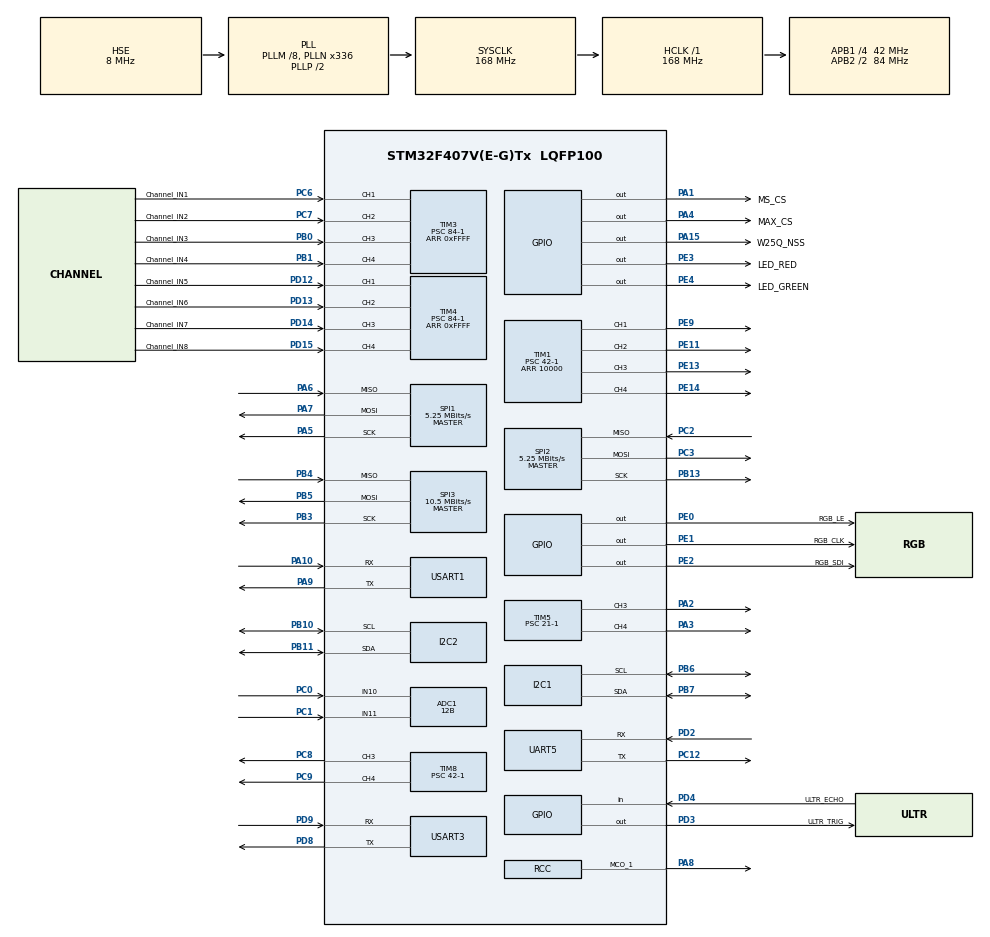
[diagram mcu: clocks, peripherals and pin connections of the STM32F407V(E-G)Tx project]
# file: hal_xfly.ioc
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ADC1.Channel-0\#ChannelRegularConversion=ADC_CHANNEL_10
ADC1.Channel-1\#ChannelRegularConversion=ADC_CHANNEL_11
ADC1.ClockPrescaler=ADC_CLOCK_SYNC_PCLK_DIV6
ADC1.ContinuousConvMode=ENABLE
ADC1.DMAContinuousRequests=DISABLE
ADC1.DataAlign=ADC_DATAALIGN_RIGHT
ADC1.DiscontinuousConvMode=DISABLE
ADC1.EOCSelection=ADC_EOC_SINGLE_CONV
ADC1.EnableAnalogWatchDog=false
ADC1.ExternalTrigConv=ADC_SOFTWARE_START
ADC1.ExternalTrigConvEdge=ADC_EXTERNALTRIGCONVEDGE_NONE
ADC1.InjNumberOfConversion=0
ADC1.NbrOfConversion=2
ADC1.NbrOfConversionFlag=1
ADC1.Rank-0\#ChannelRegularConversion=1
ADC1.Rank-1\#ChannelRegularConversion=2
ADC1.Resolution=ADC_RESOLUTION_12B
ADC1.SamplingTime-0\#ChannelRegularConversion=ADC_SAMPLETIME_56CYCLES
ADC1.SamplingTime-1\#ChannelRegularConversion=ADC_SAMPLETIME_56CYCLES
ADC1.ScanConvMode=ENABLE
ADC1.master=1
Dma.ADC1.4.Direction=DMA_PERIPH_TO_MEMORY
Dma.ADC1.4.FIFOMode=DMA_FIFOMODE_DISABLE
Dma.ADC1.4.Instance=DMA2_Stream0
Dma.ADC1.4.MemDataAlignment=DMA_MDATAALIGN_HALFWORD
Dma.ADC1.4.MemInc=DMA_MINC_ENABLE
Dma.ADC1.4.Mode=DMA_NORMAL
Dma.ADC1.4.PeriphDataAlignment=DMA_PDATAALIGN_HALFWORD
Dma.ADC1.4.PeriphInc=DMA_PINC_DISABLE
Dma.ADC1.4.Priority=DMA_PRIORITY_LOW
Dma.Request0=USART3_RX
Dma.Request1=USART3_TX
Dma.Request2=USART1_RX
Dma.Request3=USART1_TX
Dma.Request4=ADC1
Dma.USART1_RX.2.Direction=DMA_PERIPH_TO_MEMORY
Dma.USART1_RX.2.FIFOMode=DMA_FIFOMODE_DISABLE
Dma.USART1_RX.2.Instance=DMA2_Stream2
Dma.USART1_RX.2.MemDataAlignment=DMA_MDATAALIGN_BYTE
Dma.USART1_RX.2.MemInc=DMA_MINC_ENABLE
Dma.USART1_RX.2.Mode=DMA_NORMAL
Dma.USART1_RX.2.PeriphDataAlignment=DMA_PDATAALIGN_BYTE
Dma.USART1_RX.2.PeriphInc=DMA_PINC_DISABLE
Dma.USART1_RX.2.Priority=DMA_PRIORITY_HIGH
Dma.USART1_TX.3.Direction=DMA_MEMORY_TO_PERIPH
Dma.USART1_TX.3.FIFOMode=DMA_FIFOMODE_DISABLE
Dma.USART1_TX.3.Instance=DMA2_Stream7
Dma.USART1_TX.3.MemDataAlignment=DMA_MDATAALIGN_BYTE
Dma.USART1_TX.3.MemInc=DMA_MINC_ENABLE
Dma.USART1_TX.3.Mode=DMA_NORMAL
Dma.USART1_TX.3.PeriphDataAlignment=DMA_PDATAALIGN_BYTE
Dma.USART1_TX.3.PeriphInc=DMA_PINC_DISABLE
Dma.USART1_TX.3.Priority=DMA_PRIORITY_HIGH
Dma.USART3_RX.0.Direction=DMA_PERIPH_TO_MEMORY
Dma.USART3_RX.0.FIFOMode=DMA_FIFOMODE_DISABLE
Dma.USART3_RX.0.Instance=DMA1_Stream1
Dma.USART3_RX.0.MemDataAlignment=DMA_MDATAALIGN_BYTE
Dma.USART3_RX.0.MemInc=DMA_MINC_ENABLE
Dma.USART3_RX.0.Mode=DMA_NORMAL
Dma.USART3_RX.0.PeriphDataAlignment=DMA_PDATAALIGN_BYTE
Dma.USART3_RX.0.PeriphInc=DMA_PINC_DISABLE
Dma.USART3_RX.0.Priority=DMA_PRIORITY_HIGH
Dma.USART3_TX.1.Direction=DMA_MEMORY_TO_PERIPH
Dma.USART3_TX.1.FIFOMode=DMA_FIFOMODE_DISABLE
Dma.USART3_TX.1.Instance=DMA1_Stream3
Dma.USART3_TX.1.MemDataAlignment=DMA_MDATAALIGN_BYTE
Dma.USART3_TX.1.MemInc=DMA_MINC_ENABLE
Dma.USART3_TX.1.Mode=DMA_NORMAL
Dma.USART3_TX.1.PeriphDataAlignment=DMA_PDATAALIGN_BYTE
Dma.USART3_TX.1.PeriphInc=DMA_PINC_DISABLE
Dma.USART3_TX.1.Priority=DMA_PRIORITY_HIGH
Mcu.Family=STM32F4
Mcu.Name=STM32F407V(E-G)Tx
Mcu.Package=LQFP100
NVIC.DMA1_Stream1_IRQn=true\:0\:0\:false\:false\:true\:false
NVIC.DMA1_Stream3_IRQn=true\:0\:0\:false\:false\:true\:false
NVIC.DMA2_Stream0_IRQn=true\:0\:0\:false\:false\:true\:false
NVIC.DMA2_Stream2_IRQn=true\:0\:0\:false\:false\:true\:false
NVIC.DMA2_Stream7_IRQn=true\:0\:0\:false\:false\:true\:false
NVIC.PriorityGroup=NVIC_PRIORITYGROUP_4
NVIC.TIM3_IRQn=true\:0\:0\:false\:false\:true\:true
NVIC.TIM4_IRQn=true\:0\:0\:false\:false\:true\:true
NVIC.TIM6_DAC_IRQn=true\:0\:0\:false\:false\:true\:true
NVIC.UART5_IRQn=true\:0\:0\:false\:false\:true\:true
PA1.GPIO_Label=MS_CS
PA1.GPIO_Speed=GPIO_SPEED_FREQ_HIGH
PA1.PinState=GPIO_PIN_SET
PA1.Signal=GPIO_Output
PA10.Mode=Asynchronous
PA10.Signal=USART1_RX
PA13.Mode=Serial_Wire
PA13.Signal=SYS_JTMS-SWDIO
PA14.Mode=Serial_Wire
PA14.Signal=SYS_JTCK-SWCLK
PA15.GPIO_Label=W25Q_NSS
PA15.GPIO_Speed=GPIO_SPEED_FREQ_MEDIUM
PA15.PinState=GPIO_PIN_SET
PA15.Signal=GPIO_Output
PA2.Signal=S_TIM5_CH3
PA3.Signal=S_TIM5_CH4
PA4.GPIO_Label=MAX_CS
PA4.GPIO_PuPd=GPIO_PULLUP
PA4.GPIO_Speed=GPIO_SPEED_FREQ_HIGH
PA4.PinState=GPIO_PIN_SET
PA4.Signal=GPIO_Output
PA5.GPIO_Speed=GPIO_SPEED_FREQ_HIGH
PA5.Mode=Full_Duplex_Master
PA5.Signal=SPI1_SCK
PA6.GPIO_Speed=GPIO_SPEED_FREQ_HIGH
PA6.Mode=Full_Duplex_Master
PA6.Signal=SPI1_MISO
PA7.GPIO_Speed=GPIO_SPEED_FREQ_HIGH
PA7.Mode=Full_Duplex_Master
PA7.Signal=SPI1_MOSI
PA8.GPIO_Speed=GPIO_SPEED_FREQ_MEDIUM
PA8.Mode=Clock-out-1
PA8.Signal=RCC_MCO_1
PA9.Mode=Asynchronous
PA9.Signal=USART1_TX
PB0.GPIO_Label=Channel_IN3
PB0.GPIO_PuPd=GPIO_PULLUP
PB0.GPIO_Speed=GPIO_SPEED_FREQ_VERY_HIGH
PB0.Signal=S_TIM3_CH3
PB1.GPIO_Label=Channel_IN4
PB1.GPIO_PuPd=GPIO_PULLUP
PB1.GPIO_Speed=GPIO_SPEED_FREQ_VERY_HIGH
PB1.Signal=S_TIM3_CH4
PB10.GPIO_Speed=GPIO_SPEED_FREQ_HIGH
PB10.Mode=I2C
PB10.Signal=I2C2_SCL
PB11.GPIO_Speed=GPIO_SPEED_FREQ_HIGH
PB11.Mode=I2C
PB11.Signal=I2C2_SDA
PB13.Mode=Full_Duplex_Master
PB13.Signal=SPI2_SCK
PB3.Mode=Full_Duplex_Master
PB3.Signal=SPI3_SCK
PB4.Mode=Full_Duplex_Master
PB4.Signal=SPI3_MISO
PB5.Mode=Full_Duplex_Master
PB5.Signal=SPI3_MOSI
PB6.GPIO_Speed=GPIO_SPEED_FREQ_HIGH
PB6.Mode=I2C
PB6.Signal=I2C1_SCL
PB7.GPIO_Speed=GPIO_SPEED_FREQ_HIGH
PB7.Mode=I2C
PB7.Signal=I2C1_SDA
PC0.Signal=ADCx_IN10
PC1.Signal=ADCx_IN11
PC12.Mode=Asynchronous
PC12.Signal=UART5_TX
PC2.GPIO_Speed=GPIO_SPEED_FREQ_VERY_HIGH
PC2.Mode=Full_Duplex_Master
PC2.Signal=SPI2_MISO
PC3.Mode=Full_Duplex_Master
PC3.Signal=SPI2_MOSI
PC6.GPIO_Label=Channel_IN1
PC6.GPIO_PuPd=GPIO_PULLUP
PC6.GPIO_Speed=GPIO_SPEED_FREQ_VERY_HIGH
PC6.Signal=S_TIM3_CH1
PC7.GPIO_Label=Channel_IN2
PC7.GPIO_PuPd=GPIO_PULLUP
PC7.GPIO_Speed=GPIO_SPEED_FREQ_VERY_HIGH
PC7.Signal=S_TIM3_CH2
PC8.Signal=S_TIM8_CH3
PC9.Signal=S_TIM8_CH4
PD12.GPIO_Label=Channel_IN5
PD12.GPIO_PuPd=GPIO_PULLUP
PD12.GPIO_Speed=GPIO_SPEED_FREQ_VERY_HIGH
PD12.Signal=S_TIM4_CH1
PD13.GPIO_Label=Channel_IN6
PD13.GPIO_PuPd=GPIO_PULLUP
PD13.GPIO_Speed=GPIO_SPEED_FREQ_VERY_HIGH
PD13.Signal=S_TIM4_CH2
PD14.GPIO_Label=Channel_IN7
PD14.GPIO_PuPd=GPIO_PULLUP
PD14.GPIO_Speed=GPIO_SPEED_FREQ_VERY_HIGH
PD14.Signal=S_TIM4_CH3
PD15.GPIO_Label=Channel_IN8
PD15.GPIO_PuPd=GPIO_PULLUP
PD15.GPIO_Speed=GPIO_SPEED_FREQ_VERY_HIGH
PD15.Signal=S_TIM4_CH4
PD2.Mode=Asynchronous
PD2.Signal=UART5_RX
PD3.GPIO_Label=ULTR_TRIG
PD3.Signal=GPIO_Output
PD4.GPIO_Label=ULTR_ECHO
PD4.Signal=GPIO_Input
PD8.Mode=Asynchronous
PD8.Signal=USART3_TX
PD9.Mode=Asynchronous
PD9.Signal=USART3_RX
PE0.GPIO_Label=RGB_LE
PE0.GPIO_Speed=GPIO_SPEED_FREQ_HIGH
PE0.PinState=GPIO_PIN_SET
PE0.Signal=GPIO_Output
PE1.GPIO_Label=RGB_CLK
PE1.GPIO_Speed=GPIO_SPEED_FREQ_HIGH
PE1.Signal=GPIO_Output
PE11.Signal=S_TIM1_CH2
PE13.Signal=S_TIM1_CH3
PE14.Signal=S_TIM1_CH4
PE2.GPIO_Label=RGB_SDI
PE2.GPIO_Speed=GPIO_SPEED_FREQ_HIGH
PE2.Signal=GPIO_Output
PE3.GPIO_Label=LED_RED
PE3.PinState=GPIO_PIN_SET
PE3.Signal=GPIO_Output
PE4.GPIO_Label=LED_GREEN
PE4.PinState=GPIO_PIN_SET
PE4.Signal=GPIO_Output
PE9.Signal=S_TIM1_CH1
PH0-OSC_IN.Mode=HSE-External-Oscillator
PH0-OSC_IN.Signal=RCC_OSC_IN
PH1-OSC_OUT.Mode=HSE-External-Oscillator
PH1-OSC_OUT.Signal=RCC_OSC_OUT
ProjectManager.HeapSize=0x200
ProjectManager.StackSize=0x400
ProjectManager.TargetToolchain=MDK-ARM V5
RCC.48MHZClocksFreq_Value=84000000
RCC.AHBFreq_Value=168000000
RCC.APB1CLKDivider=RCC_HCLK_DIV4
RCC.APB1Freq_Value=42000000
RCC.APB1TimFreq_Value=84000000
RCC.APB2CLKDivider=RCC_HCLK_DIV2
RCC.APB2Freq_Value=84000000
RCC.APB2TimFreq_Value=168000000
RCC.CortexFreq_Value=168000000
RCC.HCLKFreq_Value=168000000
RCC.HSE_VALUE=8000000
RCC.HSI_VALUE=16000000
RCC.LSE_VALUE=32768
RCC.PLLM=8
RCC.PLLN=336
RCC.PLLSourceVirtual=RCC_PLLSOURCE_HSE
RCC.SYSCLKFreq_VALUE=168000000
RCC.SYSCLKSource=RCC_SYSCLKSOURCE_PLLCLK
RCC.VCOOutputFreq_Value=336000000
SH.ADCx_IN10.0=ADC1_IN10,IN10
SH.ADCx_IN11.0=ADC1_IN11,IN11
SH.S_TIM1_CH1.0=TIM1_CH1,PWM Generation1 CH1
SH.S_TIM1_CH2.0=TIM1_CH2,PWM Generation2 CH2
SH.S_TIM1_CH3.0=TIM1_CH3,PWM Generation3 CH3
SH.S_TIM1_CH4.0=TIM1_CH4,PWM Generation4 CH4
SH.S_TIM3_CH1.0=TIM3_CH1,Input_Capture1_from_TI1
SH.S_TIM3_CH2.0=TIM3_CH2,Input_Capture2_from_TI2
SH.S_TIM3_CH3.0=TIM3_CH3,Input_Capture3_from_TI3
SH.S_TIM3_CH4.0=TIM3_CH4,Input_Capture4_from_TI4
SH.S_TIM4_CH1.0=TIM4_CH1,Input_Capture1_from_TI1
SH.S_TIM4_CH2.0=TIM4_CH2,Input_Capture2_from_TI2
SH.S_TIM4_CH3.0=TIM4_CH3,Input_Capture3_from_TI3
SH.S_TIM4_CH4.0=TIM4_CH4,Input_Capture4_from_TI4
SH.S_TIM5_CH3.0=TIM5_CH3,PWM Generation3 CH3
SH.S_TIM5_CH4.0=TIM5_CH4,PWM Generation4 CH4
SH.S_TIM8_CH3.0=TIM8_CH3,PWM Generation3 CH3
SH.S_TIM8_CH4.0=TIM8_CH4,PWM Generation4 CH4
SPI1.BaudRatePrescaler=SPI_BAUDRATEPRESCALER_16
SPI1.CLKPhase=SPI_PHASE_2EDGE
SPI1.CLKPolarity=SPI_POLARITY_HIGH
SPI1.CalculateBaudRate=5.25 MBits/s
SPI1.Direction=SPI_DIRECTION_2LINES
SPI1.Mode=SPI_MODE_MASTER
SPI1.VirtualType=VM_MASTER
SPI2.BaudRatePrescaler=SPI_BAUDRATEPRESCALER_8
SPI2.CLKPhase=SPI_PHASE_2EDGE
SPI2.CLKPolarity=SPI_POLARITY_HIGH
SPI2.CalculateBaudRate=5.25 MBits/s
SPI2.Direction=SPI_DIRECTION_2LINES
SPI2.Mode=SPI_MODE_MASTER
SPI2.VirtualType=VM_MASTER
SPI3.BaudRatePrescaler=SPI_BAUDRATEPRESCALER_4
SPI3.CLKPhase=SPI_PHASE_2EDGE
SPI3.CLKPolarity=SPI_POLARITY_HIGH
SPI3.CalculateBaudRate=10.5 MBits/s
SPI3.Direction=SPI_DIRECTION_2LINES
SPI3.Mode=SPI_MODE_MASTER
SPI3.VirtualType=VM_MASTER
TIM1.Channel-PWM\ Generation1\ CH1=TIM_CHANNEL_1
TIM1.Channel-PWM\ Generation2\ CH2=TIM_CHANNEL_2
TIM1.Channel-PWM\ Generation3\ CH3=TIM_CHANNEL_3
TIM1.Channel-PWM\ Generation4\ CH4=TIM_CHANNEL_4
TIM1.Period=10000
TIM1.Prescaler=42-1
TIM1.Pulse-PWM\ Generation1\ CH1=4000
TIM1.Pulse-PWM\ Generation2\ CH2=4000
TIM1.Pulse-PWM\ Generation3\ CH3=4000
TIM1.Pulse-PWM\ Generation4\ CH4=4000
TIM3.Channel-Input_Capture1_from_TI1=TIM_CHANNEL_1
TIM3.Channel-Input_Capture2_from_TI2=TIM_CHANNEL_2
TIM3.Channel-Input_Capture3_from_TI3=TIM_CHANNEL_3
TIM3.Channel-Input_Capture4_from_TI4=TIM_CHANNEL_4
TIM3.ICFilter_CH1=10
TIM3.ICFilter_CH2=10
TIM3.ICFilter_CH3=10
TIM3.ICFilter_CH4=10
TIM3.ICPolarity_CH1=TIM_INPUTCHANNELPOLARITY_BOTHEDGE
TIM3.ICPolarity_CH2=TIM_INPUTCHANNELPOLARITY_BOTHEDGE
TIM3.ICPolarity_CH3=TIM_INPUTCHANNELPOLARITY_BOTHEDGE
TIM3.ICPolarity_CH4=TIM_INPUTCHANNELPOLARITY_BOTHEDGE
TIM3.Period=0xFFFF
TIM3.Prescaler=84-1
TIM4.Channel-Input_Capture1_from_TI1=TIM_CHANNEL_1
TIM4.Channel-Input_Capture2_from_TI2=TIM_CHANNEL_2
TIM4.Channel-Input_Capture3_from_TI3=TIM_CHANNEL_3
TIM4.Channel-Input_Capture4_from_TI4=TIM_CHANNEL_4
TIM4.ICFilter_CH1=10
TIM4.ICFilter_CH2=10
TIM4.ICFilter_CH3=10
TIM4.ICFilter_CH4=10
TIM4.ICPolarity_CH1=TIM_INPUTCHANNELPOLARITY_BOTHEDGE
TIM4.ICPolarity_CH2=TIM_INPUTCHANNELPOLARITY_BOTHEDGE
TIM4.ICPolarity_CH3=TIM_INPUTCHANNELPOLARITY_BOTHEDGE
TIM4.ICPolarity_CH4=TIM_INPUTCHANNELPOLARITY_BOTHEDGE
TIM4.Period=0xFFFF
TIM4.Prescaler=84-1
TIM5.Channel-PWM\ Generation3\ CH3=TIM_CHANNEL_3
TIM5.Channel-PWM\ Generation4\ CH4=TIM_CHANNEL_4
TIM5.Period=10000
TIM5.Prescaler=21-1
TIM5.Pulse-PWM\ Generation3\ CH3=4000
TIM5.Pulse-PWM\ Generation4\ CH4=4000
TIM6.Period=10
TIM6.Prescaler=83
TIM8.Channel-PWM\ Generation3\ CH3=TIM_CHANNEL_3
TIM8.Channel-PWM\ Generation4\ CH4=TIM_CHANNEL_4
TIM8.Period=10000
TIM8.Prescaler=42-1
TIM8.Pulse-PWM\ Generation3\ CH3=4000
TIM8.Pulse-PWM\ Generation4\ CH4=4000
UART5.VirtualMode=Asynchronous
USART1.VirtualMode=VM_ASYNC
USART3.VirtualMode=VM_ASYNC
VP_TIM6_VS_ClockSourceINT.Mode=Enable_Timer
board=hal_xfly

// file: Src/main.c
/**
  ******************************************************************************
  * @file           : main.c
  * @brief          : Main program body
  ******************************************************************************
  ** This notice applies to any and all portions of this file
  * that are not between comment pairs USER CODE BEGIN and
  * USER CODE END. Other portions of this file, whether
  * inserted by the user or by software development tools
  * are owned by their respective copyright owners.
  *
  * COPYRIGHT(c) 2018 STMicroelectronics
  *
  * Redistribution and use in source and binary forms, with or without modification,
  * are permitted provided that the following conditions are met:
  *   1. Redistributions of source code must retain the above copyright notice,
  *      this list of conditions and the following disclaimer.
  *   2. Redistributions in binary form must reproduce the above copyright notice,
  *      this list of conditions and the following disclaimer in the documentation
  *      and/or other materials provided with the distribution.
  *   3. Neither the name of STMicroelectronics nor the names of its contributors
  *      may be used to endorse or promote products derived from this software
  *      without specific prior written permission.
  *
  * THIS SOFTWARE IS PROVIDED BY THE COPYRIGHT HOLDERS AND CONTRIBUTORS "AS IS"
  * AND ANY EXPRESS OR IMPLIED WARRANTIES, INCLUDING, BUT NOT LIMITED TO, THE
  * IMPLIED WARRANTIES OF MERCHANTABILITY AND FITNESS FOR A PARTICULAR PURPOSE ARE
  * DISCLAIMED. IN NO EVENT SHALL THE COPYRIGHT HOLDER OR CONTRIBUTORS BE LIABLE
  * FOR ANY DIRECT, INDIRECT, INCIDENTAL, SPECIAL, EXEMPLARY, OR CONSEQUENTIAL
  * DAMAGES (INCLUDING, BUT NOT LIMITED TO, PROCUREMENT OF SUBSTITUTE GOODS OR
  * SERVICES; LOSS OF USE, DATA, OR PROFITS; OR BUSINESS INTERRUPTION) HOWEVER
  * CAUSED AND ON ANY THEORY OF LIABILITY, WHETHER IN CONTRACT, STRICT LIABILITY,
  * OR TORT (INCLUDING NEGLIGENCE OR OTHERWISE) ARISING IN ANY WAY OUT OF THE USE
  * OF THIS SOFTWARE, EVEN IF ADVISED OF THE POSSIBILITY OF SUCH DAMAGE.
  *
  ******************************************************************************
  */
#include "main.h"
#include "stm32f4xx_hal.h"
#include "adc.h"
#include "dma.h"
#include "i2c.h"
#include "spi.h"
#include "tim.h"
#include "usart.h"
#include "gpio.h"

/* USER CODE BEGIN Includes */
#include "task.h"
#include "bsp.h"

/* USER CODE END Includes */

/* USER CODE BEGIN PV */
/* Private variables ---------------------------------------------------------*/

/* USER CODE END PV */

void SystemClock_Config(void);

/* USER CODE BEGIN PFP */
/* Private function prototypes -----------------------------------------------*/

/* USER CODE END PFP */

int main(void)
{

  /* MCU Configuration----------------------------------------------------------*/

  /* Reset of all peripherals, Initializes the Flash interface and the Systick. */
  HAL_Init();

  /* Configure the system clock */
  SystemClock_Config();

  /* Initialize all configured peripherals */
  MX_GPIO_Init();
  MX_DMA_Init();
  MX_SPI1_Init();
  MX_I2C1_Init();
  MX_USART1_UART_Init();
  MX_USART3_UART_Init();
  MX_TIM3_Init();
  MX_UART5_Init();
  MX_TIM4_Init();
  MX_TIM1_Init();
  MX_TIM5_Init();
  MX_TIM8_Init();
  MX_I2C2_Init();
  MX_SPI2_Init();
  MX_ADC1_Init();
  MX_TIM6_Init();
  MX_SPI3_Init();
  /* USER CODE BEGIN 2 */
	BSP_Init();
  /* USER CODE END 2 */

  /* Infinite loop */
  /* USER CODE BEGIN WHILE */
  while (1)
  {
	AppTask();
  /* USER CODE END WHILE */

  }

}

void SystemClock_Config(void)
{

  RCC_OscInitTypeDef RCC_OscInitStruct;
  RCC_ClkInitTypeDef RCC_ClkInitStruct;

    /**Configure the main internal regulator output voltage
    */
  __HAL_RCC_PWR_CLK_ENABLE();

  __HAL_PWR_VOLTAGESCALING_CONFIG(PWR_REGULATOR_VOLTAGE_SCALE1);

    /**Initializes the CPU, AHB and APB busses clocks
    */
  RCC_OscInitStruct.OscillatorType = RCC_OSCILLATORTYPE_HSI|RCC_OSCILLATORTYPE_HSE;
  RCC_OscInitStruct.HSEState = RCC_HSE_ON;
  RCC_OscInitStruct.HSIState = RCC_HSI_ON;
  RCC_OscInitStruct.HSICalibrationValue = 16;
  RCC_OscInitStruct.PLL.PLLState = RCC_PLL_ON;
  RCC_OscInitStruct.PLL.PLLSource = RCC_PLLSOURCE_HSE;
  RCC_OscInitStruct.PLL.PLLM = 8;
  RCC_OscInitStruct.PLL.PLLN = 336;
  RCC_OscInitStruct.PLL.PLLP = RCC_PLLP_DIV2;
  RCC_OscInitStruct.PLL.PLLQ = 4;
  if (HAL_RCC_OscConfig(&RCC_OscInitStruct) != HAL_OK)
  {
    _Error_Handler(__FILE__, __LINE__);
  }

    /**Initializes the CPU, AHB and APB busses clocks
    */
  RCC_ClkInitStruct.ClockType = RCC_CLOCKTYPE_HCLK|RCC_CLOCKTYPE_SYSCLK
                              |RCC_CLOCKTYPE_PCLK1|RCC_CLOCKTYPE_PCLK2;
  RCC_ClkInitStruct.SYSCLKSource = RCC_SYSCLKSOURCE_PLLCLK;
  RCC_ClkInitStruct.AHBCLKDivider = RCC_SYSCLK_DIV1;
  RCC_ClkInitStruct.APB1CLKDivider = RCC_HCLK_DIV4;
  RCC_ClkInitStruct.APB2CLKDivider = RCC_HCLK_DIV2;

  if (HAL_RCC_ClockConfig(&RCC_ClkInitStruct, FLASH_LATENCY_5) != HAL_OK)
  {
    _Error_Handler(__FILE__, __LINE__);
  }

  HAL_RCC_MCOConfig(RCC_MCO1, RCC_MCO1SOURCE_HSI, RCC_MCODIV_1);

    /**Configure the Systick interrupt time
    */
  HAL_SYSTICK_Config(HAL_RCC_GetHCLKFreq()/1000);

    /**Configure the Systick
    */
  HAL_SYSTICK_CLKSourceConfig(SYSTICK_CLKSOURCE_HCLK);

  /* SysTick_IRQn interrupt configuration */
  HAL_NVIC_SetPriority(SysTick_IRQn, 0, 0);
}

void _Error_Handler(char *file, int line)
{
  while(1)
  {
  }
}

/************************ (C) COPYRIGHT STMicroelectronics *****END OF FILE****/
